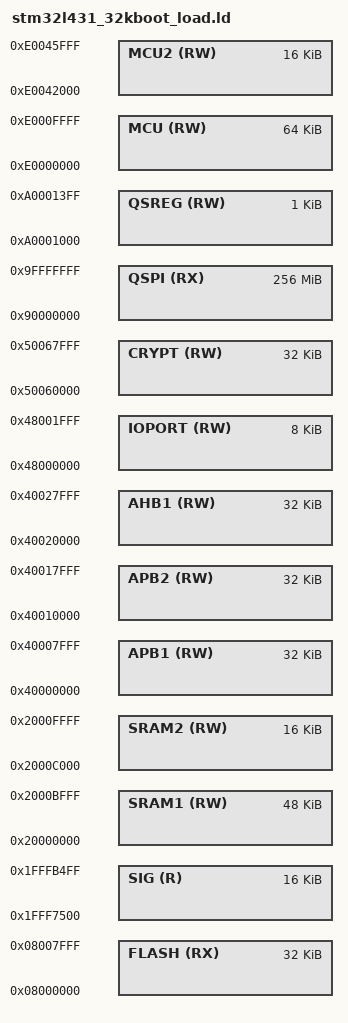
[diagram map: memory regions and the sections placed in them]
MEMORY
{
	FLASH(RX):	ORIGIN = 0x08000000, LENGTH = 32K
	SRAM1(RW):	ORIGIN = 0x20000000, LENGTH = 48K
	SRAM2(RW):	ORIGIN = 0x2000c000, LENGTH = 16K
	QSPI(RX):	ORIGIN = 0x90000000, LENGTH = 256M

	/* SFRs */
	IOPORT(RW):	ORIGIN = 0x48000000, LENGTH = 8K
	APB1(RW):	ORIGIN = 0x40000000, LENGTH = 32K
	APB2(RW):	ORIGIN = 0x40010000, LENGTH = 32K
	AHB1(RW):	ORIGIN = 0x40020000, LENGTH = 32K
	CRYPT(RW):	ORIGIN = 0x50060000, LENGTH = 32K
	MCU(RW):	ORIGIN = 0xe0000000, LENGTH = 64K
	MCU2(RW):	ORIGIN = 0xe0042000, LENGTH = 16K
	QSREG(RW):	ORIGIN = 0xa0001000, LENGTH = 1K
	SIG(R):		ORIGIN = 0x1fff7500, LENGTH = 16K
}

INCLUDE "stm32l431-base.ld"
